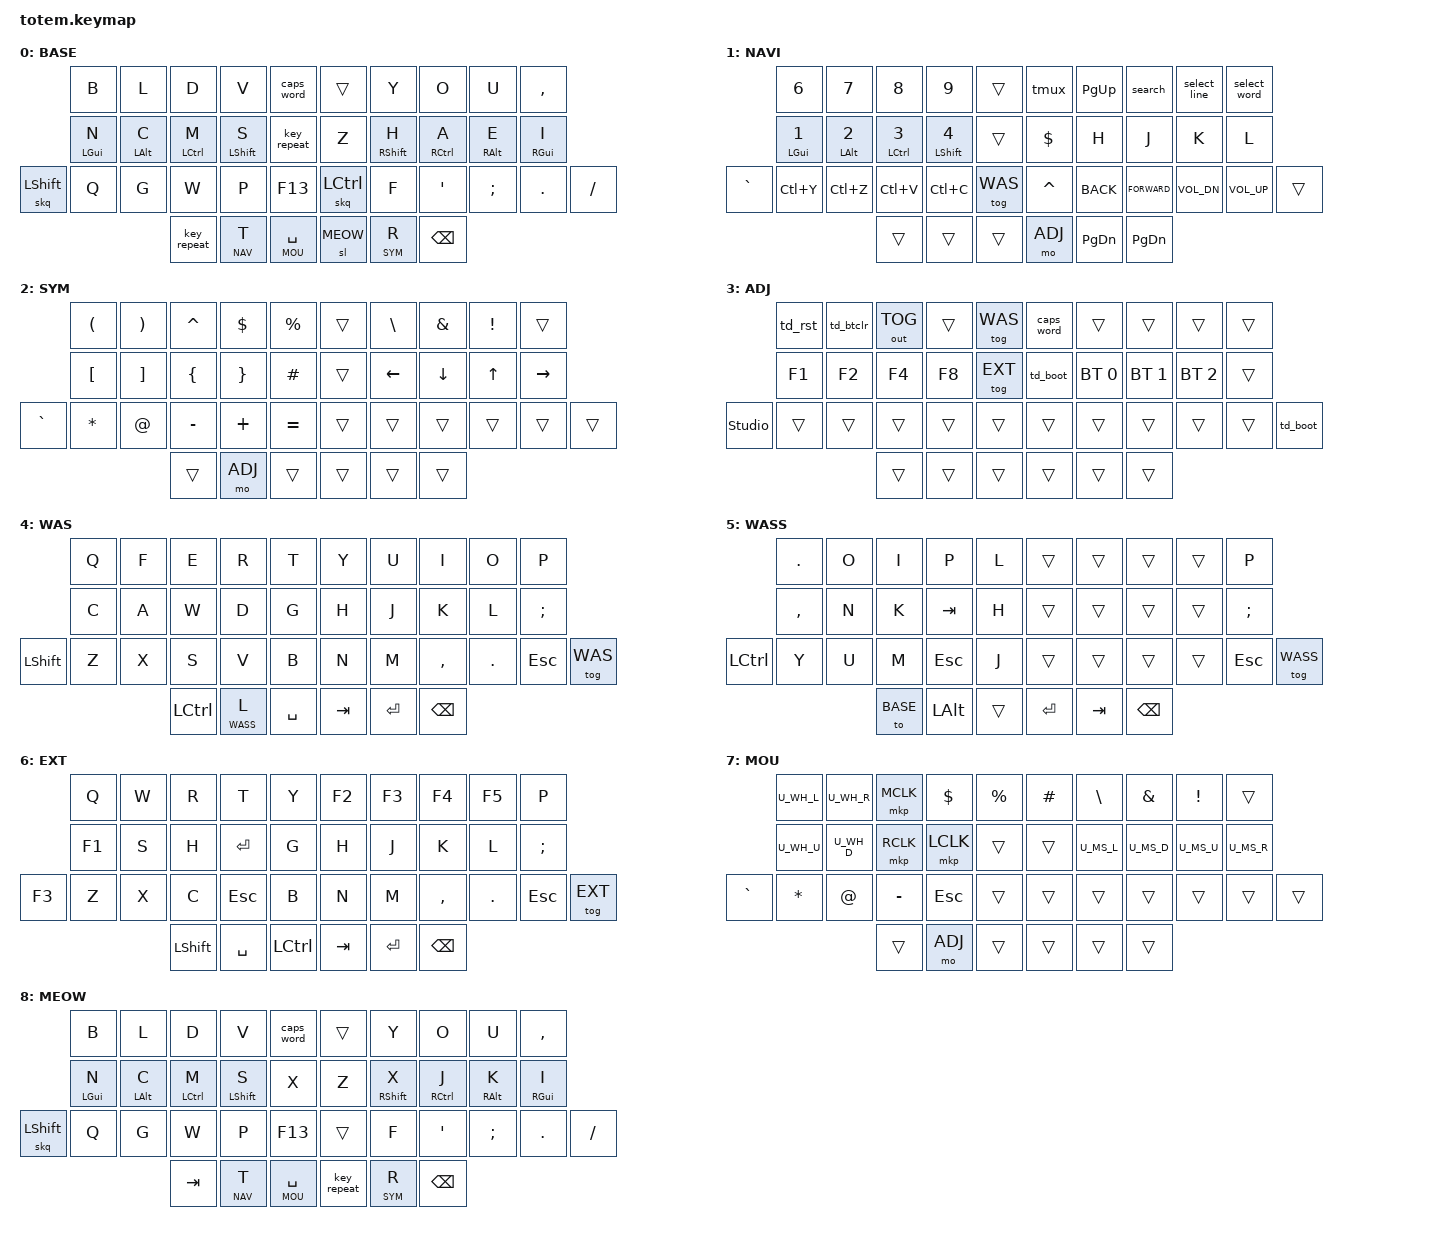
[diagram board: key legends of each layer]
//
//                                                        ▀▀▀▀▀     ▀▀▀▀▀          ▀▀█▀▀
//                                                        ▄▀▀▀▄  ▄  ▄▀▀▀▄  ▄  ▄▀▀▀▄  █  ▄▀▀▀▄
//                                                        █   █  █  █   █  █  █   █  █  █   █
//                                                         ▀▀▀   █   ▀▀▀   █   ▀▀▀   ▀   ▀▀▀
//                                                               █      ▄▄▄█▄▄▄    █   █  
//                                                               ▀      █  █  █     █▄█
//                                                             ▀▀▀▀▀    █  █  █      ▀
//                                                                      ▀  ▀  ▀
//
// ▄▄▄▄▄▄▄▄▄▄▄▄▄▄▄▄▄▄▄▄▄▄▄▄▄▄▄▄▄▄▄▄▄▄▄▄▄▄▄▄▄▄▄▄▄▄▄▄▄▄▄▄▄▄▄▄▄▄▄▄▄▄▄▄▄▄▄▄▄▄▄▄▄▄▄▄▄▄▄▄▄▄▄▄▄▄▄▄▄▄▄▄▄▄▄▄▄▄▄▄▄▄▄▄▄▄▄▄▄▄▄▄▄▄▄▄▄▄▄▄▄▄▄▄▄▄▄▄▄▄▄▄▄▄▄▄▄▄▄▄▄▄▄
       

#include <behaviors.dtsi>
#include <dt-bindings/zmk/keys.h>
#include <dt-bindings/zmk/bt.h>
#include <dt-bindings/zmk/outputs.h>
#include <dt-bindings/zmk/pointing.h>


#define LAYERS_TYPING BASE SYM NAV
#define LAYERS_NAV    NAV 
#define LAYERS_ADJ    ADJ


#define COMBO(name, out, layer_list, ...) \
    combo_##name { \
        timeout-ms = <35>; \
        key-positions = <__VA_ARGS__>; \
        bindings = <&kp out>; \
        layers = <layer_list>; \
    };


#define TAPDANCE(name, action) \
    name: name { \
        compatible = "zmk,behavior-tap-dance"; \
        #binding-cells = <0>; \
        tapping-term-ms = <300>; \
        bindings = <&none>, <action>; \
    };


#define MACRO(name, ...) \
    name: name { \
        label = #name; \
        compatible = "zmk,behavior-macro"; \
        #binding-cells = <0>; \
        bindings = <__VA_ARGS__>; \
    };


#define HRM(name, ...) \
    name: name { \
        compatible = "zmk,behavior-hold-tap"; \
        #binding-cells = <2>; \
        flavor = "balanced"; \
        require-prior-idle-ms = <150>; \
        tapping-term-ms = <280>; \
        quick-tap-ms = <175>; \
        bindings = <&kp>, <&kp>; \
        hold-trigger-key-positions = <__VA_ARGS__>; \
        hold-trigger-on-release; \
    };


#define BASE 0
#define NAV  1
#define SYM  2
#define ADJ  3
#define WAS  4
#define WASS 5
#define EXT  6
#define MOU  7
#define MEOW 8


// MUST BE HERE otherwise mou undefined when parsed 
#include "mouse.dtsi"


/ {
    behaviors {
        TAPDANCE(td_boot,  &bootloader)
        TAPDANCE(td_rst,   &sys_reset)
        TAPDANCE(td_btclr, &bt BT_CLR)
        // TODO must check
        HRM(hmr, 0 1 2 3 4 10 11 12 13 14 30 20 21 22 23 24 32 33 34)
        HRM(hml, 5 6 7 8 9 15 16 17 18 19 25 26 27 28 29 39 35 36 37)
      skq: sticky_key_quick_release {
        compatible = "zmk,behavior-sticky-key";
        #binding-cells = <1>;
        bindings = <&kp>;
        release-after-ms = <1000>;
        quick-release;
        ignore-modifiers;
      };
    };
    combos {
        compatible = "zmk,combos"; 
        COMBO(esc,  ESC,   LAYERS_TYPING, 17 18)   // H A
        COMBO(ret,  SPACE, LAYERS_TYPING, 33 36)   // s t
        COMBO(spc,  RET,   LAYERS_TYPING, 16 17)   // A E
        COMBO(del,  DEL,   LAYERS_TYPING, 7 8)     // O U
        COMBO(f13B, F13,   LAYERS_TYPING, 13 33)   // s t
        COMBO(TABB, TAB,   LAYERS_TYPING, 16 18)   // h e

        COMBO(f3,  F3,  LAYERS_ADJ, 10 11)
        COMBO(f5,  F5,  LAYERS_ADJ, 10 12)
        COMBO(f6,  F6,  LAYERS_ADJ, 11 12)
        COMBO(f7,  F7,  LAYERS_ADJ, 10 11 12)
        COMBO(f9,  F9,  LAYERS_ADJ, 10 13)
        COMBO(f10, F10, LAYERS_ADJ, 11 13)
        COMBO(f11, F11, LAYERS_ADJ, 10 11 13)
        COMBO(f12, F12, LAYERS_ADJ, 12 13)
        COMBO(f13, F13, LAYERS_ADJ, 10 12 13)
        COMBO(f14, F14, LAYERS_ADJ, 11 12 13)
        COMBO(f15, F15, LAYERS_ADJ, 10 11 12 13)

        COMBO(NUM0, N0, LAYERS_NAV, 11 12)
        COMBO(NUM5, N5, LAYERS_NAV, 12 13)
    };

    macros {
        MACRO(tmux,         &kp LC(N))
        MACRO(search,       &kp LC(C) &kp LC(T) &kp LC(V) &kp RET)
        MACRO(select_line,  &kp HOME &kp LS(END))
        MACRO(select_word,  &kp LC(LEFT) &kp LC(LS(RIGHT)))
    };

        keymap {
                compatible = "zmk,keymap";
// ▄▄▄▄▄▄▄▄▄▄▄▄▄▄▄▄▄▄▄▄▄▄▄▄▄▄▄▄▄▄▄▄▄▄▄▄▄▄▄▄▄▄▄▄▄▄▄▄▄▄▄▄▄▄▄▄▄▄▄▄▄▄▄▄▄▄▄▄▄▄▄▄▄▄▄▄▄▄▄▄▄▄▄▄▄▄▄▄▄▄▄▄▄▄▄▄▄▄▄▄▄▄▄▄▄▄▄▄▄▄▄▄▄▄▄▄▄▄▄▄▄▄▄▄▄▄▄▄▄▄▄▄▄▄▄▄▄▄▄▄▄▄▄

                base_layer {
label= "BASE"                              ;
 bindings = <

                &kp B       &kp L       &kp D        &kp V         &caps_word           &trans      &kp Y        &kp O        &kp U       &kp COMMA
                &hml LGUI N &hml LALT C &hml LCTRL M &hml LSHFT S  &key_repeat          &kp Z       &hmr RSHFT H &hmr RCTRL A &hmr RALT E &hmr RGUI I
    &skq LSHFT  &kp Q       &kp G       &kp W        &kp P         &kp F13              &skq LCTRL  &kp F        &kp SQT      &kp SEMI    &kp DOT     &kp FSLH
                                        &key_repeat  &lt NAV T     &lt MOU SPACE        &sl MEOW    &lt SYM R    &kp BSPC
                        >; // TODO momentary layer for jk. also gl fy wd pv 
                };

// ▄▄▄▄▄▄▄▄▄▄▄▄▄▄▄▄▄▄▄▄▄▄▄▄▄▄▄▄▄▄▄▄▄▄▄▄▄▄▄▄▄▄▄▄▄▄▄▄▄▄▄▄▄▄▄▄▄▄▄▄▄▄▄▄▄▄▄▄▄▄▄▄▄▄▄▄▄▄▄▄▄▄▄▄▄▄▄▄▄▄▄▄▄▄▄▄▄▄▄▄▄▄▄▄▄▄▄▄▄▄▄▄▄▄▄▄▄▄▄▄▄▄▄▄▄▄▄▄▄▄▄▄▄▄▄▄▄▄▄▄▄▄▄


                nav_layer {
label= "NAVI"                              ;
 bindings = <

                &kp N6       &kp N7       &kp N8        &kp N9        &trans           &tmux         &kp PG_UP   &search       &select_line  &select_word
                &hml LGUI N1 &hml LALT N2 &hml LCTRL N3 &hml LSHFT N4 &trans           &kp DOLLAR    &kp H       &kp J         &kp K         &kp L 
    &kp GRAVE   &kp LC(Y)    &kp LC(Z)    &kp LC(V)     &kp LC(C)     &tog WAS         &kp CARET     &kp K_BACK  &kp K_FORWARD &kp C_VOL_DN  &kp C_VOL_UP     &trans
                                          &trans        &trans        &trans           &mo ADJ       &kp PG_DN   &kp PG_DN
                        >;
                };

// ▄▄▄▄▄▄▄▄▄▄▄▄▄▄▄▄▄▄▄▄▄▄▄▄▄▄▄▄▄▄▄▄▄▄▄▄▄▄▄▄▄▄▄▄▄▄▄▄▄▄▄▄▄▄▄▄▄▄▄▄▄▄▄▄▄▄▄▄▄▄▄▄▄▄▄▄▄▄▄▄▄▄▄▄▄▄▄▄▄▄▄▄▄▄▄▄▄▄▄▄▄▄▄▄▄▄▄▄▄▄▄▄▄▄▄▄▄▄▄▄▄▄▄▄▄▄▄▄▄▄▄▄▄▄▄▄▄▄▄▄▄▄▄


                sym_layer {
label= "SYM"                               ;
 bindings = <

                &kp LEFT_PARENTHESIS    &kp RIGHT_PARENTHESIS  &kp CARET      &kp DOLLAR      &kp PRCNT            &trans   &kp BSLH  &kp AMPERSAND &kp EXCLAMATION &trans       
                &kp LEFT_BRACKET        &kp RIGHT_BRACKET      &kp LEFT_BRACE &kp RIGHT_BRACE &kp HASH             &trans   &kp LEFT  &kp DOWN      &kp UP          &kp RIGHT 
    &kp GRAVE   &kp STAR                &kp AT                 &kp MINUS      &kp PLUS        &kp EQUAL            &trans   &trans    &trans        &trans          &trans      &trans
                                                               &trans         &mo ADJ         &trans               &trans   &trans    &trans      
                        >;
                };

// ▄▄▄▄▄▄▄▄▄▄▄▄▄▄▄▄▄▄▄▄▄▄▄▄▄▄▄▄▄▄▄▄▄▄▄▄▄▄▄▄▄▄▄▄▄▄▄▄▄▄▄▄▄▄▄▄▄▄▄▄▄▄▄▄▄▄▄▄▄▄▄▄▄▄▄▄▄▄▄▄▄▄▄▄▄▄▄▄▄▄▄▄▄▄▄▄▄▄▄▄▄▄▄▄▄▄▄▄▄▄▄▄▄▄▄▄▄▄▄▄▄▄▄▄▄▄▄▄▄▄▄▄▄▄▄▄▄▄▄▄▄▄▄


                adjust_layer {
label= "ADJ"                               ;
 bindings = <

                   &td_rst     &td_btclr    &out OUT_TOG &trans       &tog WAS         &caps_word  &trans     &trans     &trans     &trans
                   &kp F1      &kp F2       &kp F4       &kp F8       &tog EXT         &td_boot    &bt BT_SEL 0 &bt BT_SEL 1 &bt BT_SEL 2     &trans  
    &studio_unlock &trans      &trans       &trans       &trans       &trans           &trans      &trans     &trans     &trans     &trans     &td_boot         
                                            &trans       &trans       &trans           &trans      &trans      &trans      
                        >;
                };

// ▄▄▄▄▄▄▄▄▄▄▄▄▄▄▄▄▄▄▄▄▄▄▄▄▄▄▄▄▄▄▄▄▄▄▄▄▄▄▄▄▄▄▄▄▄▄▄▄▄▄▄▄▄▄▄▄▄▄▄▄▄▄▄▄▄▄▄▄▄▄▄▄▄▄▄▄▄▄▄▄▄▄▄▄▄▄▄▄▄▄▄▄▄▄▄▄▄▄▄▄▄▄▄▄▄▄▄▄▄▄▄▄▄▄▄▄▄▄▄▄▄▄▄▄▄▄▄▄▄▄▄▄▄▄▄▄▄▄▄▄▄▄▄

                was_layer {
label= "WAS"                              ;
 bindings = <

                &kp Q       &kp F       &kp E       &kp R       &kp T                  &kp Y       &kp U       &kp I       &kp O       &kp P
                &kp C       &kp A       &kp W       &kp D       &kp G                  &kp H       &kp J       &kp K       &kp L       &kp SEMI
    &kp LSHFT   &kp Z       &kp X       &kp S       &kp V       &kp B                  &kp N       &kp M       &kp COMMA   &kp DOT     &kp ESC    &tog WAS
                                        &kp LCTRL   &lt WASS L  &kp SPACE              &kp TAB     &kp RET     &kp BSPC
                        >;
                };

// ▄▄▄▄▄▄▄▄▄▄▄▄▄▄▄▄▄▄▄▄▄▄▄▄▄▄▄▄▄▄▄▄▄▄▄▄▄▄▄▄▄▄▄▄▄▄▄▄▄▄▄▄▄▄▄▄▄▄▄▄▄▄▄▄▄▄▄▄▄▄▄▄▄▄▄▄▄▄▄▄▄▄▄▄▄▄▄▄▄▄▄▄▄▄▄▄▄▄▄▄▄▄▄▄▄▄▄▄▄▄▄▄▄▄▄▄▄▄▄▄▄▄▄▄▄▄▄▄▄▄▄▄▄▄▄▄▄▄▄▄▄▄▄


                wass_layer {
label= "WASS"                              ;
 bindings = <

                &kp DOT     &kp O       &kp I       &kp P       &kp L                  &trans      &trans      &trans       &trans      &kp P
                &kp COMMA   &kp N       &kp K       &kp TAB     &kp H                  &trans      &trans      &trans       &trans      &kp SEMI
    &kp LCTRL   &kp Y       &kp U       &kp M       &kp ESC     &kp J                  &trans      &trans      &trans       &trans      &kp ESC    &tog WASS
                                        &to BASE    &kp LALT    &trans                 &kp RET     &kp TAB     &kp BSPC
                        >;
                };

// ▄▄▄▄▄▄▄▄▄▄▄▄▄▄▄▄▄▄▄▄▄▄▄▄▄▄▄▄▄▄▄▄▄▄▄▄▄▄▄▄▄▄▄▄▄▄▄▄▄▄▄▄▄▄▄▄▄▄▄▄▄▄▄▄▄▄▄▄▄▄▄▄▄▄▄▄▄▄▄▄▄▄▄▄▄▄▄▄▄▄▄▄▄▄▄▄▄▄▄▄▄▄▄▄▄▄▄▄▄▄▄▄▄▄▄▄▄▄▄▄▄▄▄▄▄▄▄▄▄▄▄▄▄▄▄▄▄▄▄▄▄▄▄


                ext_layer {
label= "EXT"                              ;
 bindings = <

                &kp Q       &kp W       &kp R       &kp T       &kp Y                  &kp F2      &kp F3      &kp F4      &kp F5      &kp P
                &kp F1      &kp S       &kp H       &kp RET     &kp G                  &kp H       &kp J       &kp K       &kp L       &kp SEMI
    &kp F3      &kp Z       &kp X       &kp C       &kp ESC     &kp B                  &kp N       &kp M       &kp COMMA   &kp DOT     &kp ESC    &tog EXT
                                        &kp LSHFT   &kp SPACE   &kp LCTRL              &kp TAB     &kp RET     &kp BSPC
                        >;
                };

// ▄▄▄▄▄▄▄▄▄▄▄▄▄▄▄▄▄▄▄▄▄▄▄▄▄▄▄▄▄▄▄▄▄▄▄▄▄▄▄▄▄▄▄▄▄▄▄▄▄▄▄▄▄▄▄▄▄▄▄▄▄▄▄▄▄▄▄▄▄▄▄▄▄▄▄▄▄▄▄▄▄▄▄▄▄▄▄▄▄▄▄▄▄▄▄▄▄▄▄▄▄▄▄▄▄▄▄▄▄▄▄▄▄▄▄▄▄▄▄▄▄▄▄▄▄▄▄▄▄▄▄▄▄▄▄▄▄▄▄▄▄▄▄

                mou_layer {
label= "MOU"                              ;
 bindings = <

                U_WH_L      U_WH_R  &mkp MCLK     &kp DOLLAR    &kp PRCNT              &kp HASH &kp BSLH &kp AMPERSAND &kp EXCLAMATION &trans       
                U_WH_U      U_WH_D  &mkp RCLK     &mkp LCLK     &trans                 &trans   U_MS_L   U_MS_D         U_MS_U         U_MS_R 
    &kp GRAVE   &kp STAR    &kp AT  &kp MINUS     &kp ESC       &trans                 &trans   &trans   &trans         &trans         &trans     &trans        
                                    &trans        &mo ADJ       &trans                 &trans   &trans   &trans      
                        >;
                };

// ▄▄▄▄▄▄▄▄▄▄▄▄▄▄▄▄▄▄▄▄▄▄▄▄▄▄▄▄▄▄▄▄▄▄▄▄▄▄▄▄▄▄▄▄▄▄▄▄▄▄▄▄▄▄▄▄▄▄▄▄▄▄▄▄▄▄▄▄▄▄▄▄▄▄▄▄▄▄▄▄▄▄▄▄▄▄▄▄▄▄▄▄▄▄▄▄▄▄▄▄▄▄▄▄▄▄▄▄▄▄▄▄▄▄▄▄▄▄▄▄▄▄▄▄▄▄▄▄▄▄▄▄▄▄▄▄▄▄▄▄▄▄▄

                meow_layer {
label= "MEOW"                              ;
 bindings = <

                &kp B       &kp L       &kp D        &kp V         &caps_word           &trans      &kp Y        &kp O        &kp U       &kp COMMA
                &hml LGUI N &hml LALT C &hml LCTRL M &hml LSHFT S  &kp X                &kp Z       &hmr RSHFT X &hmr RCTRL J &hmr RALT K &hmr RGUI I
    &skq LSHFT  &kp Q       &kp G       &kp W        &kp P         &kp F13              &trans      &kp F        &kp SQT      &kp SEMI    &kp DOT     &kp FSLH
                                        &kp TAB      &lt NAV T     &lt MOU SPACE        &key_repeat &lt SYM R    &kp BSPC
                        >;
                };

// ▄▄▄▄▄▄▄▄▄▄▄▄▄▄▄▄▄▄▄▄▄▄▄▄▄▄▄▄▄▄▄▄▄▄▄▄▄▄▄▄▄▄▄▄▄▄▄▄▄▄▄▄▄▄▄▄▄▄▄▄▄▄▄▄▄▄▄▄▄▄▄▄▄▄▄▄▄▄▄▄▄▄▄▄▄▄▄▄▄▄▄▄▄▄▄▄▄▄▄▄▄▄▄▄▄▄▄▄▄▄▄▄▄▄▄▄▄▄▄▄▄▄▄▄▄▄▄▄▄▄▄▄▄▄▄▄▄▄▄▄▄▄▄
        };
};
